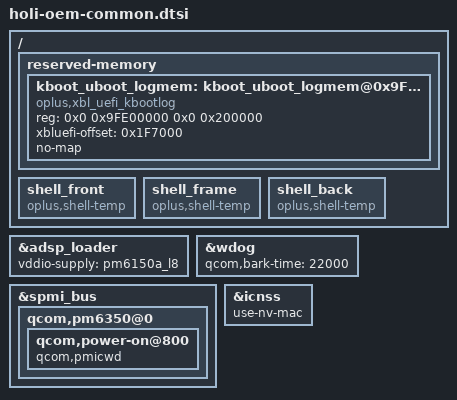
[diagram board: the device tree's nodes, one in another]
/* DTB: Platform related generic modifications */
#include "../qcom/holi.dtsi"

&adsp_loader {
//ifdef OPLUS_FEATURE_SENSOR_DRIVER
//tangweiqin@BSP,Sensor,20201216,modify for sensor 1.8v always on
        vddio-supply = <&pm6150a_l8>;
//endif
};

&wdog {
		qcom,bark-time = <22000>;
};

// xbl_uefi_mem address get from boot_images Core.fdf file: PcdEmbeddedFdBaseAddress + SERIAL_BUFFER_OFFSET,0x9FC00000+0x3F7000=0x9FFF7000
// kernel boot log: 0x9FE00000~ 0x9FFF7000
/ {
	reserved-memory {
		kboot_uboot_logmem: kboot_uboot_logmem@0x9FE00000 {
			reg = <0x0 0x9FE00000 0x0 0x200000>;
			compatible = "oplus,xbl_uefi_kbootlog";
			xbluefi-offset = <0x1F7000>;
			no-map;
		};
	};
};

&spmi_bus {
	qcom,pm6350@0 {
		qcom,power-on@800 {
			qcom,pmicwd;
		};
	};
};

//#ifdef OPLUS_BUG_STABILITY
&icnss {
	use-nv-mac;
};
//#endif /* OPLUS_BUG_STABILITY */

//#ifdef OPLUS_FEATURE_THERMAL_HORAE
/ {
        shell_front {
                compatible = "oplus,shell-temp";
        };

        shell_frame {
                compatible = "oplus,shell-temp";
        };

        shell_back {
                compatible = "oplus,shell-temp";
        };
};
//#endif





